VERSION ""

NS_ :

BS_:

BU_: DBG VCU BMS MCM

BO_ 100 DRIVER_HEARTBEAT: 1 DRIVER
 SG_ DRIVER_HEARTBEAT_cmd : 0|8@1+ (1,0) [0|0] "" SENSOR,MOTOR

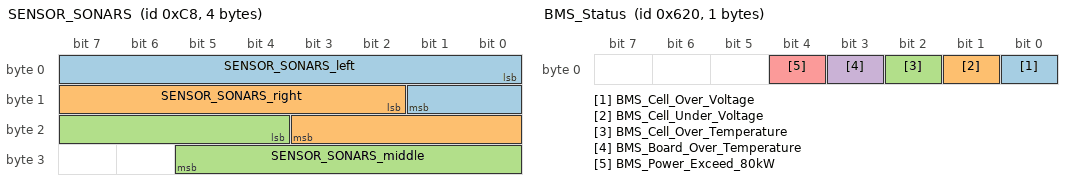
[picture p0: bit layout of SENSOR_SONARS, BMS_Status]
BO_ 200 SENSOR_SONARS: 4 SENSOR
 SG_ SENSOR_SONARS_left : 0|10@1+ (1,0) [0|800] "inch" DRIVER
 SG_ SENSOR_SONARS_right : 10|10@1+ (1,0) [0|0] "inch" DRIVER
 SG_ SENSOR_SONARS_middle : 20|10@1+ (1,0) [0|0] "inch" DRIVER

BO_ 1568 BMS_Status: 1 BMS
 SG_ BMS_Cell_Over_Voltage : 0|1@1+ (1,0) [0|0] "" VCU
 SG_ BMS_Cell_Under_Voltage : 1|1@1+ (1,0) [0|0] "" VCU
 SG_ BMS_Cell_Over_Temperature : 2|1@1+ (1,0) [0|0] "" VCU
 SG_ BMS_Board_Over_Temperature : 3|1@1+ (1,0) [0|0] "" VCU
 SG_ BMS_Power_Exceed_80kW : 4|1@1+ (1,0) [0|0] "" VCU

BO_ 1571 BMS_Status: 8 BMS
 SG_ BMS_Pack_Voltage : 0|4@1+ (0.01,0) [0|6.56] "V" VCU
 SG_ BMS_Pack_Current : 4|4@1+ (1,0) [0|0] "A" VCU

BO_ 1571 BMS_Status: 8 BMS
 SG_ BMS_Pack_Voltage : 0|4@1+ (0.01,0) [0|6.56] "V" VCU
 SG_ BMS_Pack_Current : 4|4@1+ (1,0) [0|0] "A" VCU

CM_ BU_ DRIVER "The driver controller driving the car";
CM_ BU_ MOTOR "The motor controller of the car";
CM_ BU_ SENSOR "The sensor controller of the car";
CM_ BO_ 100 "Sync message used to synchronize the controllers";
CM_ SG_ 100 DRIVER_HEARTBEAT_cmd "Heartbeat command from the driver";
CM_ BO_ 300 "Acceleration data of the car";

BA_DEF_ "BusType" STRING ;
BA_DEF_ BO_ "GenMsgCycleTime" INT 0 0;
BA_DEF_ SG_ "FieldType" STRING ;

BA_DEF_DEF_ "BusType" "CAN";
BA_DEF_DEF_ "FieldType" "";
BA_DEF_DEF_ "GenMsgCycleTime" 0;

BA_ "GenMsgCycleTime" BO_ 100 1000;
BA_ "GenMsgCycleTime" BO_ 200 50;
BA_ "GenMsgCycleTime" BO_ 200 100;
BA_ "FieldType" SG_ 100 DRIVER_HEARTBEAT_cmd "DRIVER_HEARTBEAT_cmd";

VAL_ 100 DRIVER_HEARTBEAT_cmd 2 "DRIVER_HEARTBEAT_cmd_REBOOT" 1 "DRIVER_HEARTBEAT_cmd_SYNC" 0 "DRIVER_HEARTBEAT_cmd_NOOP" ;
